# SCB register map
Vendor: Texas Instruments
Peripheral module from a debugger description file (folder CC23x0R5).
Registers are 32-bit, access per field, reset 0x0 unless marked. A register's access mark holds for its fields unless they carry their own. Offsets are as the file gives them; lines under a group give offsets from that group; [hi:lo] are bit positions; {n}, {i} and the like mark numbered series; 'fields as' and 'values as' point back to an identical list; <NAME> marks a mode.

## SCB
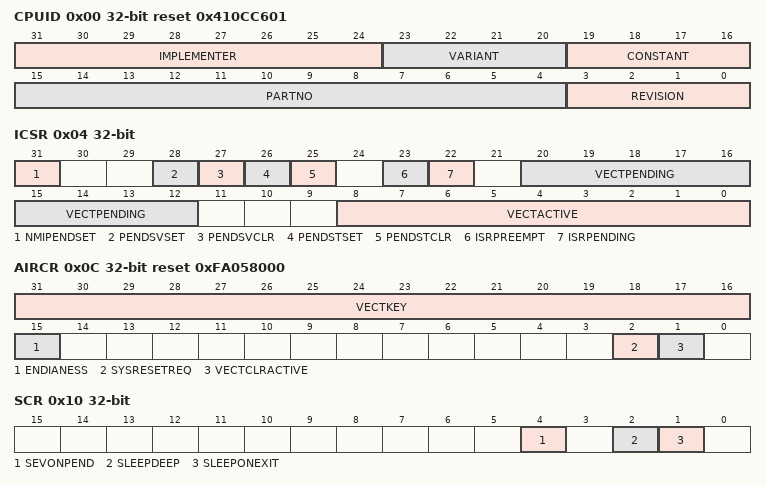
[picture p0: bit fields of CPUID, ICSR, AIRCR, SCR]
0x00 CPUID ro reset 0x410CC601 — CPUID Base Register Read the CPU ID Base Register to determine: the ID number of the processor core, the version number of the processor core, the implementation details of the processor core.
  [31:24] IMPLEMENTER — Implementor code: 0x41 = ARM
  [23:20] VARIANT — Implementation defined variant number: 0x0 (for r0)
  [19:16] CONSTANT — Reads as 0xC
  [15:4] PARTNO — Number of processor within family: 0xC20
  [3:0] REVISION — Implementation defined revision number: 0x1 = processor p1 revision.
0x04 ICSR — Interrupt Control State Register Use the Interrupt Control State Register to set a pending Non-Maskable Interrupt (NMI), set or clear a pending PendSV, set or clear a pending SysTick, check for pending exceptions, check the vector number of the highest priority pended exception, check the vector number of the active exception.
  [31] NMIPENDSET rw — Setting this bit will activate an NMI. Since NMI is the highest priority exception, it will activate as soon as it is registered. Reads back with current state (1 if Pending, 0 if not). 0x0:No effect 0x1:Set pending nmi
  [28] PENDSVSET rw — Set pending PendSV bit. On reads this bit returns the pending state of PendSV 0x0:No effect 0x1:Set pending pendsv
  [27] PENDSVCLR wo — Clear pending PendSV bit 0x0:No effect 0x1:Clear pending pendsv
  [26] PENDSTSET rw — Set a pending SysTick bit. On reads this bit returns the pending state of SysTick. 0x0:No effect 0x1:Set pending systick
  [25] PENDSTCLR wo — Clear pending SysTick bit 0x0:No effect 0x1:Clear pending systick
  [23] ISRPREEMPT ro — The system can only access this bit when the core is halted. It indicates that a pending interrupt is to be taken in the next running cycle. If C_MASKINTS is clear in the Debug Halting Control and Status Register, the interrupt is serviced. 0x0:A pending exception is not serviced. 0x1:A pending exception is serviced on exit from the debug halt state
  [22] ISRPENDING ro — External interrupt pending flag 0x0:Interrupt not pending 0x1:Interrupt pending
  [20:12] VECTPENDING ro — Indicates the exception number for the highest priority pending exception: 0 = no pending exceptions. Non zero = The pending state includes the effect of memory-mapped enable and mask registers. It does not include the PRIMASK special-purpose register qualifier.
  [8:0] VECTACTIVE ro — Active exception number field. Reset clears the VECTACTIVE field.
0x08 VTOR — Vector Table Offset Register The VTOR holds the vector table offset address.
  [31:8] TBLOFF rw — Bits [31:8] of the indicate the vector table offset address.
0x0C AIRCR reset 0xFA058000 — Application Interrupt and Reset Control Register Use the Application Interrupt and Reset Control Register to: determine data endianness, clear all active state information from debug halt mode, request a system reset.
  [31:16] VECTKEY wo — Register key. To write to other parts of this register, you must ensure 0x5FA is written into the VECTKEY field.
  [15] ENDIANESS ro — Data endianness bit. The read value depends on the endian configuration implemented 0x0:Little endian 0x1:Be-8 big-endian
  [2] SYSRESETREQ wo — Writing 1 to this bit causes the SYSRESETREQ signal to the outer system to be asserted to request a reset. The intention is to force a large system reset of all major components except for debug. The C_HALT bit in the DHCSR is cleared as a result of the system reset requested. The debugger does not lose contact with the device.
  [1] VECTCLRACTIVE wo — Clears all active state information for fixed and configurable exceptions. This bit: is self-clearing, can only be set by the DAP when the core is halted. When set: clears all active exception status of the processor, forces a return to Thread mode, forces an IPSR of 0. A debugger must re-initialize the stack.
0x10 SCR — System Control Register System Control Register. Use the System Control Register for power-management functions: signal to the system when the processor can enter a low power state, control how the processor enters and exits low power states.
  [4] SEVONPEND rw — When enabled, this causes WFE to wake up when an interrupt moves from inactive to pended. Otherwise, WFE only wakes up from an event signal, external and SEV instruction generated. The event input, RXEV, is registered even when not waiting for an event, and so effects the next WFE.
  [2] SLEEPDEEP rw — Sleep deep bit.
    1=DSLP_EN (indicates to the system that Cortex-M0 clock can be stopped. Setting this bit causes the SLEEPDEEP port to be asserted when the processor can be stopped.); 0=DSLP_DIS (not OK to turn off system clock)
  [1] SLEEPONEXIT rw — Sleep on exit when returning from Handler mode to Thread mode. Enables interrupt driven applications to avoid returning to empty main application.
    1=SLP_EN (Sleep on return to thread mode); 0=SLP_DIS (Do not sleep when returning to thread mode)
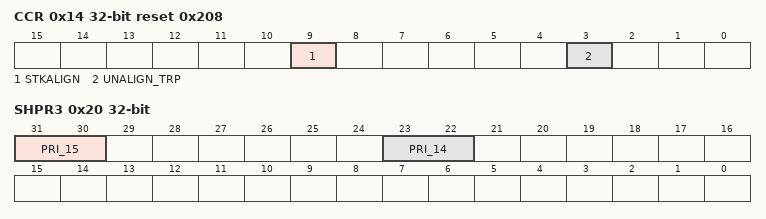
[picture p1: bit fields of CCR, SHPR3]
0x14 CCR ro reset 0x208 — Configuration and Control Register The Configuration and Control Register permanently enables stack alignment and causes unaligned accesses to result in a Hard Fault.
  [9] STKALIGN — Always set to 1. On exception entry, all exceptions are entered with 8-byte stack alignment and the context to restore it is saved. The SP is restored on the associated exception return.
  [3] UNALIGN_TRP — Indicates that all unaligned accesses results in a Hard Fault. Trap for unaligned access is fixed at 1.
0x1C SHPR2 — System Handler Priority Register 2 System handlers are a special class of exception handler that can have their priority set to any of the priority levels. Use the System Handler Priority Register 2 to set the priority of SVCall.
  [31:30] PRI_11 rw — Priority of system handler 11, SVCall
0x20 SHPR3 — System Handler Priority Register 3 System handlers are a special class of exception handler that can have their priority set to any of the priority levels. Use the System Handler Priority Register 3 to set the priority of PendSV and SysTick.
  [31:30] PRI_15 rw — Priority of system handler 15, SysTick
  [23:22] PRI_14 rw — Priority of system handler 14, PendSV
0x24 SHCSR — System Handler Control and State Register Use the System Handler Control and State Register to determine or clear the pending status of SVCall.
  [15] SVCALLPENDED rw — Reads as 1 if SVCall is Pending. Write 1 to set pending SVCall, write 0 to clear pending SVCall.
